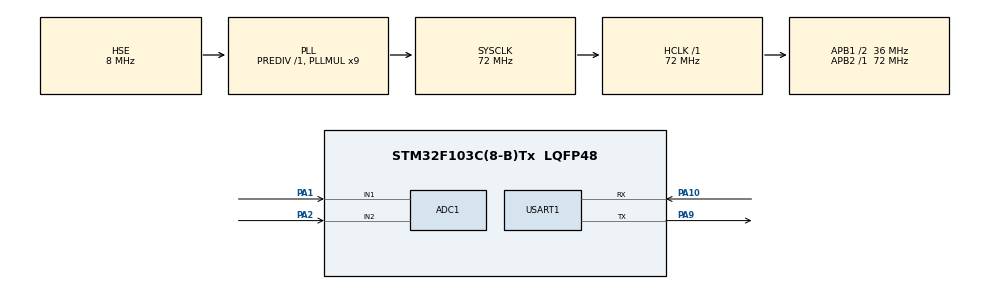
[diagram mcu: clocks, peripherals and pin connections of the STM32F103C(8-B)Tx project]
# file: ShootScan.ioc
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ADC1.AWD1HighThreshold=4095
ADC1.AWD1ITMode=ENABLE
ADC1.AWD1LowThreshold=0
ADC1.Channel-0\#ChannelRegularConversion=ADC_CHANNEL_1
ADC1.Channel-1\#ChannelRegularConversion=ADC_CHANNEL_2
ADC1.ContinuousConvMode=ENABLE
ADC1.DataAlign=ADC_DATAALIGN_RIGHT
ADC1.DiscontinuousConvMode=DISABLE
ADC1.EnableAnalogWatchDog=true
ADC1.EnableRegularConversion=ENABLE
ADC1.ExternalTrigConv=ADC_SOFTWARE_START
ADC1.InjNumberOfConversion=0
ADC1.NbrOfConversion=2
ADC1.NbrOfConversionFlag=1
ADC1.Rank-0\#ChannelRegularConversion=1
ADC1.Rank-1\#ChannelRegularConversion=2
ADC1.SamplingTime-0\#ChannelRegularConversion=ADC_SAMPLETIME_239CYCLES_5
ADC1.SamplingTime-1\#ChannelRegularConversion=ADC_SAMPLETIME_239CYCLES_5
ADC1.ScanConvMode=ADC_SCAN_ENABLE
ADC1.WatchdogMode=ADC_ANALOGWATCHDOG_ALL_REG
ADC1.master=1
Dma.ADC1.0.Direction=DMA_PERIPH_TO_MEMORY
Dma.ADC1.0.Instance=DMA1_Channel1
Dma.ADC1.0.MemDataAlignment=DMA_MDATAALIGN_HALFWORD
Dma.ADC1.0.MemInc=DMA_MINC_ENABLE
Dma.ADC1.0.Mode=DMA_CIRCULAR
Dma.ADC1.0.PeriphDataAlignment=DMA_PDATAALIGN_HALFWORD
Dma.ADC1.0.PeriphInc=DMA_PINC_DISABLE
Dma.ADC1.0.Priority=DMA_PRIORITY_VERY_HIGH
Dma.Request0=ADC1
Dma.Request1=USART1_RX
Dma.Request2=USART1_TX
Dma.USART1_RX.1.Direction=DMA_PERIPH_TO_MEMORY
Dma.USART1_RX.1.Instance=DMA1_Channel5
Dma.USART1_RX.1.MemDataAlignment=DMA_MDATAALIGN_BYTE
Dma.USART1_RX.1.MemInc=DMA_MINC_ENABLE
Dma.USART1_RX.1.Mode=DMA_NORMAL
Dma.USART1_RX.1.PeriphDataAlignment=DMA_PDATAALIGN_BYTE
Dma.USART1_RX.1.PeriphInc=DMA_PINC_DISABLE
Dma.USART1_RX.1.Priority=DMA_PRIORITY_LOW
Dma.USART1_TX.2.Direction=DMA_MEMORY_TO_PERIPH
Dma.USART1_TX.2.Instance=DMA1_Channel4
Dma.USART1_TX.2.MemDataAlignment=DMA_MDATAALIGN_BYTE
Dma.USART1_TX.2.MemInc=DMA_MINC_ENABLE
Dma.USART1_TX.2.Mode=DMA_NORMAL
Dma.USART1_TX.2.PeriphDataAlignment=DMA_PDATAALIGN_BYTE
Dma.USART1_TX.2.PeriphInc=DMA_PINC_DISABLE
Dma.USART1_TX.2.Priority=DMA_PRIORITY_LOW
Mcu.Family=STM32F1
Mcu.Name=STM32F103C(8-B)Tx
Mcu.Package=LQFP48
NVIC.ADC1_2_IRQn=true\:0\:0\:false\:false\:true\:true
NVIC.DMA1_Channel1_IRQn=true\:0\:0\:true\:false\:true\:false
NVIC.DMA1_Channel4_IRQn=true\:2\:0\:true\:false\:true\:false
NVIC.DMA1_Channel5_IRQn=true\:0\:1\:true\:false\:true\:false
NVIC.PriorityGroup=NVIC_PRIORITYGROUP_3
NVIC.TIM1_UP_IRQn=true\:1\:0\:true\:false\:true\:true
NVIC.USART1_IRQn=true\:5\:0\:true\:false\:true\:true
PA1.Signal=ADCx_IN1
PA10.Mode=Asynchronous
PA10.Signal=USART1_RX
PA13.Mode=Serial_Wire
PA13.Signal=SYS_JTMS-SWDIO
PA14.Mode=Serial_Wire
PA14.Signal=SYS_JTCK-SWCLK
PA2.Signal=ADCx_IN2
PA9.Mode=Asynchronous
PA9.Signal=USART1_TX
PD0-OSC_IN.Mode=HSE-External-Oscillator
PD0-OSC_IN.Signal=RCC_OSC_IN
PD1-OSC_OUT.Mode=HSE-External-Oscillator
PD1-OSC_OUT.Signal=RCC_OSC_OUT
ProjectManager.HeapSize=0x200
ProjectManager.StackSize=0x400
ProjectManager.TargetToolchain=MDK-ARM V5
RCC.ADCPresc=RCC_ADCPCLK2_DIV6
RCC.AHBFreq_Value=72000000
RCC.APB1CLKDivider=RCC_HCLK_DIV2
RCC.APB1Freq_Value=36000000
RCC.APB1TimFreq_Value=72000000
RCC.APB2Freq_Value=72000000
RCC.APB2TimFreq_Value=72000000
RCC.HCLKFreq_Value=72000000
RCC.PLLMUL=RCC_PLL_MUL9
RCC.PLLSourceVirtual=RCC_PLLSOURCE_HSE
RCC.SYSCLKFreq_VALUE=72000000
RCC.SYSCLKSource=RCC_SYSCLKSOURCE_PLLCLK
RCC.USBFreq_Value=72000000
SH.ADCx_IN1.0=ADC1_IN1,IN1
SH.ADCx_IN2.0=ADC1_IN2,IN2
TIM1.AutoReloadPreload=TIM_AUTORELOAD_PRELOAD_ENABLE
TIM1.Period=19999
TIM1.Prescaler=71
USART1.VirtualMode=VM_ASYNC
VP_TIM1_VS_ClockSourceINT.Mode=Internal
board=custom

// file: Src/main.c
/**
  ******************************************************************************
  * @file           : main.c
  * @brief          : Main program body
  ******************************************************************************
  ** This notice applies to any and all portions of this file
  * that are not between comment pairs USER CODE BEGIN and
  * USER CODE END. Other portions of this file, whether
  * inserted by the user or by software development tools
  * are owned by their respective copyright owners.
  *
  * COPYRIGHT(c) 2019 STMicroelectronics
  *
  * Redistribution and use in source and binary forms, with or without modification,
  * are permitted provided that the following conditions are met:
  *   1. Redistributions of source code must retain the above copyright notice,
  *      this list of conditions and the following disclaimer.
  *   2. Redistributions in binary form must reproduce the above copyright notice,
  *      this list of conditions and the following disclaimer in the documentation
  *      and/or other materials provided with the distribution.
  *   3. Neither the name of STMicroelectronics nor the names of its contributors
  *      may be used to endorse or promote products derived from this software
  *      without specific prior written permission.
  *
  * THIS SOFTWARE IS PROVIDED BY THE COPYRIGHT HOLDERS AND CONTRIBUTORS "AS IS"
  * AND ANY EXPRESS OR IMPLIED WARRANTIES, INCLUDING, BUT NOT LIMITED TO, THE
  * IMPLIED WARRANTIES OF MERCHANTABILITY AND FITNESS FOR A PARTICULAR PURPOSE ARE
  * DISCLAIMED. IN NO EVENT SHALL THE COPYRIGHT HOLDER OR CONTRIBUTORS BE LIABLE
  * FOR ANY DIRECT, INDIRECT, INCIDENTAL, SPECIAL, EXEMPLARY, OR CONSEQUENTIAL
  * DAMAGES (INCLUDING, BUT NOT LIMITED TO, PROCUREMENT OF SUBSTITUTE GOODS OR
  * SERVICES; LOSS OF USE, DATA, OR PROFITS; OR BUSINESS INTERRUPTION) HOWEVER
  * CAUSED AND ON ANY THEORY OF LIABILITY, WHETHER IN CONTRACT, STRICT LIABILITY,
  * OR TORT (INCLUDING NEGLIGENCE OR OTHERWISE) ARISING IN ANY WAY OUT OF THE USE
  * OF THIS SOFTWARE, EVEN IF ADVISED OF THE POSSIBILITY OF SUCH DAMAGE.
  *
  ******************************************************************************
  */
#include "main.h"
#include "stm32f1xx_hal.h"
#include "adc.h"
#include "dma.h"
#include "tim.h"
#include "usart.h"
#include "gpio.h"

/* USER CODE BEGIN Includes */

#include "ComToMaster.h"
#include "ShootBoard.h"

/* USER CODE END Includes */

/* USER CODE BEGIN PV */
/* Private variables ---------------------------------------------------------*/

/* USER CODE END PV */

void SystemClock_Config(void);

/* USER CODE BEGIN PFP */
/* Private function prototypes -----------------------------------------------*/

/* USER CODE END PFP */

int main(void)
{

  /* MCU Configuration----------------------------------------------------------*/

  /* Reset of all peripherals, Initializes the Flash interface and the Systick. */
  HAL_Init();

  /* Configure the system clock */
  SystemClock_Config();

  /* Initialize all configured peripherals */
  MX_GPIO_Init();
  MX_DMA_Init();
  MX_USART1_UART_Init();
  MX_ADC1_Init();
  MX_TIM1_Init();
  /* USER CODE BEGIN 2 */
  //初始化与上位机的通信组件
  Mstr_COM_ModuleInit(&Mstr_COM_Module);

  //延时等待滤波器初始化完毕
  HAL_Delay(50);

  //打开定时器
  HAL_TIM_Base_Start_IT(&htim1);

  /* USER CODE END 2 */

  /* Infinite loop */
  /* USER CODE BEGIN WHILE */
  while (1)
  {
    DealSampleData();

  /* USER CODE END WHILE */

  }

}

void SystemClock_Config(void)
{

  RCC_OscInitTypeDef RCC_OscInitStruct;
  RCC_ClkInitTypeDef RCC_ClkInitStruct;
  RCC_PeriphCLKInitTypeDef PeriphClkInit;

    /**Initializes the CPU, AHB and APB busses clocks
    */
  RCC_OscInitStruct.OscillatorType = RCC_OSCILLATORTYPE_HSE;
  RCC_OscInitStruct.HSEState = RCC_HSE_ON;
  RCC_OscInitStruct.HSEPredivValue = RCC_HSE_PREDIV_DIV1;
  RCC_OscInitStruct.HSIState = RCC_HSI_ON;
  RCC_OscInitStruct.PLL.PLLState = RCC_PLL_ON;
  RCC_OscInitStruct.PLL.PLLSource = RCC_PLLSOURCE_HSE;
  RCC_OscInitStruct.PLL.PLLMUL = RCC_PLL_MUL9;
  if (HAL_RCC_OscConfig(&RCC_OscInitStruct) != HAL_OK)
  {
    _Error_Handler(__FILE__, __LINE__);
  }

    /**Initializes the CPU, AHB and APB busses clocks
    */
  RCC_ClkInitStruct.ClockType = RCC_CLOCKTYPE_HCLK|RCC_CLOCKTYPE_SYSCLK
                              |RCC_CLOCKTYPE_PCLK1|RCC_CLOCKTYPE_PCLK2;
  RCC_ClkInitStruct.SYSCLKSource = RCC_SYSCLKSOURCE_PLLCLK;
  RCC_ClkInitStruct.AHBCLKDivider = RCC_SYSCLK_DIV1;
  RCC_ClkInitStruct.APB1CLKDivider = RCC_HCLK_DIV2;
  RCC_ClkInitStruct.APB2CLKDivider = RCC_HCLK_DIV1;

  if (HAL_RCC_ClockConfig(&RCC_ClkInitStruct, FLASH_LATENCY_2) != HAL_OK)
  {
    _Error_Handler(__FILE__, __LINE__);
  }

  PeriphClkInit.PeriphClockSelection = RCC_PERIPHCLK_ADC;
  PeriphClkInit.AdcClockSelection = RCC_ADCPCLK2_DIV6;
  if (HAL_RCCEx_PeriphCLKConfig(&PeriphClkInit) != HAL_OK)
  {
    _Error_Handler(__FILE__, __LINE__);
  }

    /**Configure the Systick interrupt time
    */
  HAL_SYSTICK_Config(HAL_RCC_GetHCLKFreq()/1000);

    /**Configure the Systick
    */
  HAL_SYSTICK_CLKSourceConfig(SYSTICK_CLKSOURCE_HCLK);

  /* SysTick_IRQn interrupt configuration */
  HAL_NVIC_SetPriority(SysTick_IRQn, 0, 0);
}

void _Error_Handler(char *file, int line)
{
  while(1)
  {
  }
}

/************************ (C) COPYRIGHT STMicroelectronics *****END OF FILE****/
